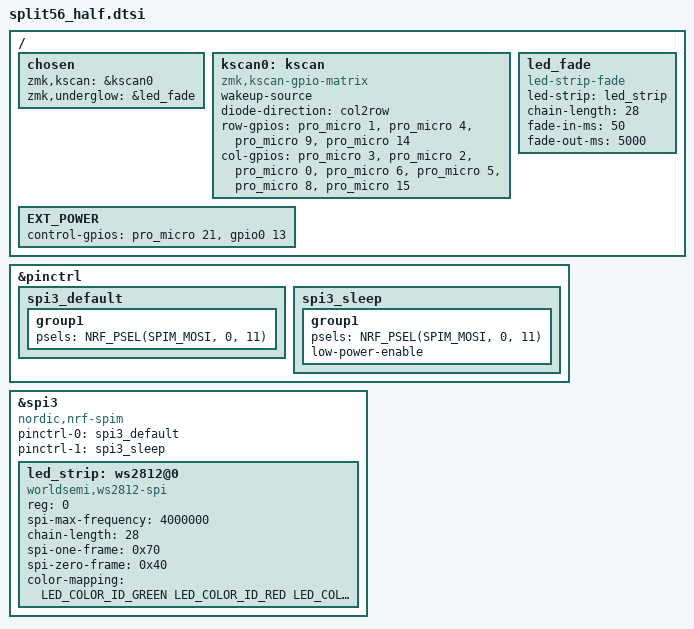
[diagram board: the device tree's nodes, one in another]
/* Generated by tools/zmk_generate.py from pcb/pins.yaml and layout/generated/. Do not edit. */

/* What both halves share: the key matrix, the LED chain and the LED supply switch. */

#include "split56.dtsi"
#include <dt-bindings/led/led.h>

/ {
    chosen {
        zmk,kscan = &kscan0;
        zmk,underglow = &led_fade;
    };

    kscan0: kscan {
        compatible = "zmk,kscan-gpio-matrix";
        wakeup-source;

        diode-direction = "col2row";
        row-gpios  // R1, R2, R3, R4
            = <&pro_micro 1 (GPIO_ACTIVE_HIGH | GPIO_PULL_DOWN)>
            , <&pro_micro 4 (GPIO_ACTIVE_HIGH | GPIO_PULL_DOWN)>
            , <&pro_micro 9 (GPIO_ACTIVE_HIGH | GPIO_PULL_DOWN)>
            , <&pro_micro 14 (GPIO_ACTIVE_HIGH | GPIO_PULL_DOWN)>
            ;
        col-gpios  // C0, C1, C2, C3, C4, C5, T
            = <&pro_micro 3 GPIO_ACTIVE_HIGH>
            , <&pro_micro 2 GPIO_ACTIVE_HIGH>
            , <&pro_micro 0 GPIO_ACTIVE_HIGH>
            , <&pro_micro 6 GPIO_ACTIVE_HIGH>
            , <&pro_micro 5 GPIO_ACTIVE_HIGH>
            , <&pro_micro 8 GPIO_ACTIVE_HIGH>
            , <&pro_micro 15 GPIO_ACTIVE_HIGH>
            ;
    };

    /*
     * The board's external power node (same name, so this extends it). LED_EN on the PCB
     * switches the LED supply; P0.13 is the module's own 3.3 V output, as on a stock
     * nice!nano, which nothing on this PCB uses.
     */
    EXT_POWER {
        control-gpios = <&pro_micro 21 GPIO_ACTIVE_HIGH>, <&gpio0 13 GPIO_ACTIVE_HIGH>;
    };

    /*
     * The lighting goes through this to the LED chain (firmware/src/led_strip_fade.c): black
     * to full over fade-in-ms when it lights, and full to black over the last fade-out-ms
     * before ZMK's idle timeout, which then switches the lighting and its supply off.
     */
    led_fade: led_fade {
        compatible = "led-strip-fade";
        led-strip = <&led_strip>;
        chain-length = <28>;
        fade-in-ms = <50>;
        fade-out-ms = <5000>;
    };
};

&pinctrl {
    spi3_default: spi3_default {
        group1 {
            psels = <NRF_PSEL(SPIM_MOSI, 0, 11)>;
        };
    };

    spi3_sleep: spi3_sleep {
        group1 {
            psels = <NRF_PSEL(SPIM_MOSI, 0, 11)>;
            low-power-enable;
        };
    };
};

&spi3 {
    compatible = "nordic,nrf-spim";
    status = "okay";

    pinctrl-0 = <&spi3_default>;
    pinctrl-1 = <&spi3_sleep>;
    pinctrl-names = "default", "sleep";

    led_strip: ws2812@0 {
        compatible = "worldsemi,ws2812-spi";

        /* SPI */
        reg = <0>; /* ignored, but necessary for SPI bindings */
        spi-max-frequency = <4000000>;

        /* SK6812MINI-E: WS2812 protocol, green first (datasheet) */
        chain-length = <28>;
        spi-one-frame = <0x70>;
        spi-zero-frame = <0x40>;
        color-mapping = <LED_COLOR_ID_GREEN LED_COLOR_ID_RED LED_COLOR_ID_BLUE>;
    };
};
